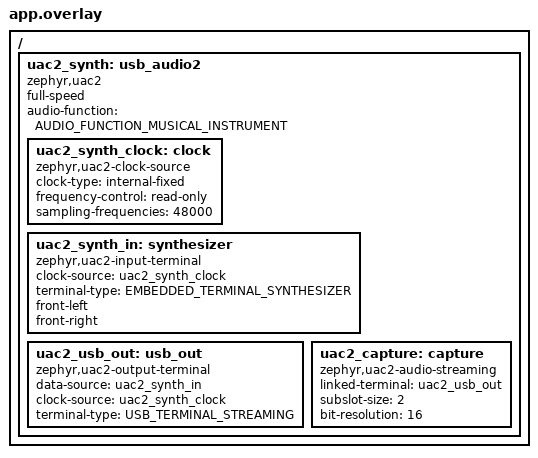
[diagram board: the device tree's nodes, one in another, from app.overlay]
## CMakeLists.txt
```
# SPDX-License-Identifier: Apache-2.0
cmake_minimum_required(VERSION 3.20.0)
find_package(Zephyr REQUIRED HINTS $ENV{ZEPHYR_BASE})
project(sp1_usb_audio_sample)

# This sample has no watchdog feed, no power-off and no LEDs. Flashed on an
# SP-1 it would reset every 5 s (the bootloader's watchdog) with no way to turn
# the unit off. See README.md, "Running on an SP-1".
if(BOARD STREQUAL "sp1")
  message(FATAL_ERROR "sample: not for the sp1 board as it stands -- the SP-1 firmware is ../../sp1/")
endif()

# sample_usbd: Zephyr's device_next helper that builds the USB device from the
# classes enabled in devicetree and Kconfig.
include(${ZEPHYR_BASE}/samples/subsys/usb/common/common.cmake)

# The shared USB audio code: the glue and the packet regulator.
set(USB_AUDIO ${CMAKE_CURRENT_SOURCE_DIR}/../../usb-audio)
target_sources(app PRIVATE src/main.c ${USB_AUDIO}/usb_audio.c ${USB_AUDIO}/uacring.c)
target_include_directories(app PRIVATE ${USB_AUDIO})

# The ring is single-producer single-consumer across a thread and the USB
# stack (or, with the fast path, the USBD interrupt): full barriers on target.
set_source_files_properties(${USB_AUDIO}/uacring.c PROPERTIES
  COMPILE_DEFINITIONS "UACRING_BARRIER=barrier_dmem_fence_full"
  COMPILE_OPTIONS "-include;zephyr/sys/barrier.h")

# Optional: the ISO IN fast path, in place of Zephyr's nRF USBD driver.
# Build with -DEXTRA_CONF_FILE=isofast.conf.
include(${CMAKE_CURRENT_SOURCE_DIR}/../../module/nrf-usbd-isofast/CMakeLists.txt)
```

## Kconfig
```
# SPDX-License-Identifier: Apache-2.0

# CONFIG_SAMPLE_USBD_VID/PID/PRODUCT/..., consumed by sample_usbd_init.c.
source "samples/subsys/usb/common/Kconfig.sample_usbd"

# CONFIG_UDC_NRF_ISOFAST: the optional fast-path driver.
rsource "../../module/nrf-usbd-isofast/Kconfig"

source "Kconfig.zephyr"
```

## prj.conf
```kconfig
# SPDX-License-Identifier: Apache-2.0

# Zephyr's newer USB device stack and its UAC2 (USB Audio Class 2) function.
CONFIG_USB_DEVICE_STACK_NEXT=y
CONFIG_USBD_AUDIO2_CLASS=y
# The nRF USBD driver enables its start-of-frame interrupt only with this set.
# The class forwards each SOF to uac2_ops.sof_cb, which sends one packet.
CONFIG_UDC_ENABLE_SOF=y

# Zephyr's test VID/PID. Use your own for anything you distribute.
CONFIG_SAMPLE_USBD_PRODUCT="UAC2 tone sample"
CONFIG_SAMPLE_USBD_MAX_POWER=50

CONFIG_HWINFO=y
CONFIG_PRINTK=y
CONFIG_LOG=n
```

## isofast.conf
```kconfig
# SPDX-License-Identifier: Apache-2.0
# Optional: replace Zephyr's nRF USBD driver with nrf-usbd-isofast's copy,
# whose ISO IN fast path sends each packet from the SOF interrupt with no thread
# wake-up. ../../module/nrf-usbd-isofast/README.md says when this is worth it.
CONFIG_UDC_NRF=n
CONFIG_UDC_NRF_ISOFAST=y
```

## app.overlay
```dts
/* SPDX-License-Identifier: Apache-2.0
 *
 * One UAC2 function: a 48 kHz, 16-bit stereo capture stream to the host --
 * the device appears as an audio INPUT on the computer. No ISO OUT and no
 * feedback endpoint, so nothing but the capture stream needs SOF events.
 */
#include <zephyr/dt-bindings/usb/audio.h>

/ {
	uac2_synth: usb_audio2 {
		compatible = "zephyr,uac2";
		status = "okay";
		full-speed;
		audio-function = <AUDIO_FUNCTION_MUSICAL_INSTRUMENT>;

		uac2_synth_clock: clock {
			compatible = "zephyr,uac2-clock-source";
			clock-type = "internal-fixed";
			frequency-control = "read-only";
			sampling-frequencies = <48000>;
		};

		uac2_synth_in: synthesizer {
			compatible = "zephyr,uac2-input-terminal";
			clock-source = <&uac2_synth_clock>;
			terminal-type = <EMBEDDED_TERMINAL_SYNTHESIZER>;
			front-left;
			front-right;
		};

		uac2_usb_out: usb_out {
			compatible = "zephyr,uac2-output-terminal";
			data-source = <&uac2_synth_in>;
			clock-source = <&uac2_synth_clock>;
			terminal-type = <USB_TERMINAL_STREAMING>;
		};

		uac2_capture: capture {
			compatible = "zephyr,uac2-audio-streaming";
			linked-terminal = <&uac2_usb_out>;
			subslot-size = <2>;
			bit-resolution = <16>;
		};
	};
};
```

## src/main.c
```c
/* SPDX-License-Identifier: Apache-2.0
 *
 * UAC2 tone sample: a 1 kHz sine at -12 dBFS, 48 kHz stereo, to the host as a
 * USB audio input.
 *
 * The producer stands in for a real audio path. On an SP-1 the audio thread is
 * paced by the I2S codec's clock, one block at a time; here a thread is paced by
 * the system timer and renders however many frames the timer says are due.
 * Either way the audio runs on a clock that is not the host's USB frame clock,
 * which is exactly the drift the packet regulator (uacring.c) absorbs.
 */
#include <math.h>
#include <stdint.h>

#include <sample_usbd.h>
#include <zephyr/kernel.h>
#include <zephyr/sys/printk.h>
#include <zephyr/usb/usbd.h>

#include "usb_audio.h"

#define RATE        48000u
#define TONE_PERIOD 48u          /* 1 kHz at 48 kHz: a whole cycle in 48 frames */
#define MAX_CHUNK   256u
#define TICK_MS     2

static int16_t sine[TONE_PERIOD];
static int16_t chunk[MAX_CHUNK * 2u];

int main(void)
{
	for (uint32_t i = 0; i < TONE_PERIOD; i++) {
		/* -12 dBFS: a quarter of full scale. */
		sine[i] = (int16_t)(8192.0f * sinf(2.0f * 3.14159265f * (float)i / TONE_PERIOD));
	}

	usb_audio_init();
	struct usbd_context *ctx = sample_usbd_init_device(usb_audio_usbd_msg);

	if (ctx == NULL || usbd_enable(ctx) != 0) {
		printk("usb init failed\n");
		return 0;
	}

	const uint64_t hz = (uint64_t)sys_clock_hw_cycles_per_sec();
	const uint64_t start = k_cycle_get_64();
	uint64_t produced = 0;
	uint32_t phase = 0;

	for (;;) {
		k_msleep(TICK_MS);

		/* Frames due by the system clock, so the rate is exactly 48 kHz on
		 * that clock however the sleeps round. */
		uint64_t due = (k_cycle_get_64() - start) * RATE / hz;

		while (produced < due) {
			uint32_t n = (uint32_t)MIN(due - produced, (uint64_t)MAX_CHUNK);

			/* Tell the regulator what is coming BEFORE rendering it, so a
			 * slow render never looks like clock drift. On an SP-1 this is
			 * where the audio thread takes its I2S slot. */
			usb_audio_claim(n);
			for (uint32_t i = 0; i < n; i++) {
				chunk[i * 2u] = sine[phase];
				chunk[i * 2u + 1u] = sine[phase];
				phase = (phase + 1u) % TONE_PERIOD;
			}
			usb_audio_push(chunk, n);
			produced += n;
		}
	}
	return 0;
}
```
